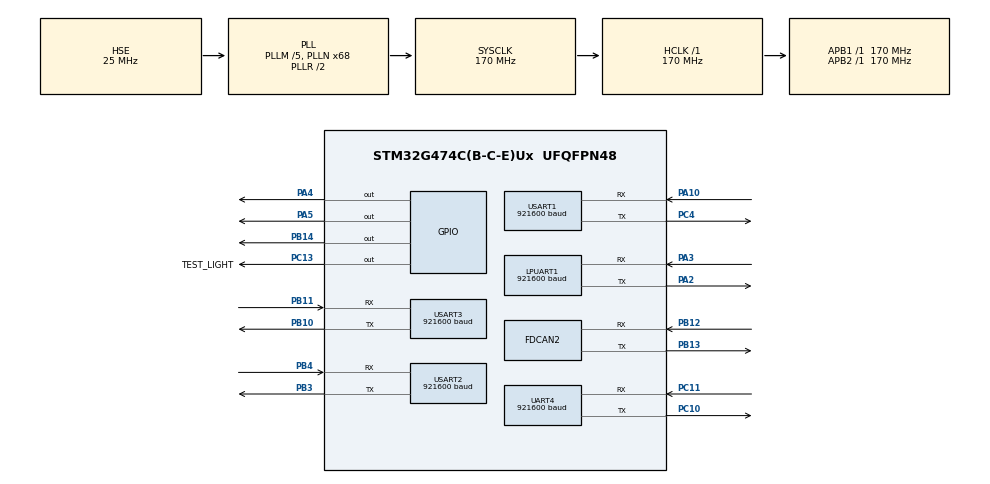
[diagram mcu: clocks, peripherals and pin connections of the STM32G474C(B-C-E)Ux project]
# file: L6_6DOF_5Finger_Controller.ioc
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Dma.LPUART1_RX.6.Direction=DMA_PERIPH_TO_MEMORY
Dma.LPUART1_RX.6.EventEnable=DISABLE
Dma.LPUART1_RX.6.Instance=DMA1_Channel3
Dma.LPUART1_RX.6.MemDataAlignment=DMA_MDATAALIGN_BYTE
Dma.LPUART1_RX.6.MemInc=DMA_MINC_ENABLE
Dma.LPUART1_RX.6.Mode=DMA_NORMAL
Dma.LPUART1_RX.6.PeriphDataAlignment=DMA_PDATAALIGN_BYTE
Dma.LPUART1_RX.6.PeriphInc=DMA_PINC_DISABLE
Dma.LPUART1_RX.6.Polarity=HAL_DMAMUX_REQ_GEN_RISING
Dma.LPUART1_RX.6.Priority=DMA_PRIORITY_MEDIUM
Dma.LPUART1_RX.6.RequestNumber=1
Dma.LPUART1_RX.6.SignalID=NONE
Dma.LPUART1_RX.6.SyncEnable=DISABLE
Dma.LPUART1_RX.6.SyncPolarity=HAL_DMAMUX_SYNC_NO_EVENT
Dma.LPUART1_RX.6.SyncRequestNumber=1
Dma.LPUART1_RX.6.SyncSignalID=NONE
Dma.LPUART1_TX.7.Direction=DMA_MEMORY_TO_PERIPH
Dma.LPUART1_TX.7.EventEnable=DISABLE
Dma.LPUART1_TX.7.Instance=DMA1_Channel4
Dma.LPUART1_TX.7.MemDataAlignment=DMA_MDATAALIGN_BYTE
Dma.LPUART1_TX.7.MemInc=DMA_MINC_ENABLE
Dma.LPUART1_TX.7.Mode=DMA_NORMAL
Dma.LPUART1_TX.7.PeriphDataAlignment=DMA_PDATAALIGN_BYTE
Dma.LPUART1_TX.7.PeriphInc=DMA_PINC_DISABLE
Dma.LPUART1_TX.7.Polarity=HAL_DMAMUX_REQ_GEN_RISING
Dma.LPUART1_TX.7.Priority=DMA_PRIORITY_MEDIUM
Dma.LPUART1_TX.7.RequestNumber=1
Dma.LPUART1_TX.7.SignalID=NONE
Dma.LPUART1_TX.7.SyncEnable=DISABLE
Dma.LPUART1_TX.7.SyncPolarity=HAL_DMAMUX_SYNC_NO_EVENT
Dma.LPUART1_TX.7.SyncRequestNumber=1
Dma.LPUART1_TX.7.SyncSignalID=NONE
Dma.Request0=USART2_RX
Dma.Request1=USART2_TX
Dma.Request2=USART3_RX
Dma.Request3=USART3_TX
Dma.Request4=UART4_RX
Dma.Request5=UART4_TX
Dma.Request6=LPUART1_RX
Dma.Request7=LPUART1_TX
Dma.UART4_RX.4.Direction=DMA_PERIPH_TO_MEMORY
Dma.UART4_RX.4.EventEnable=DISABLE
Dma.UART4_RX.4.Instance=DMA1_Channel7
Dma.UART4_RX.4.MemDataAlignment=DMA_MDATAALIGN_BYTE
Dma.UART4_RX.4.MemInc=DMA_MINC_ENABLE
Dma.UART4_RX.4.Mode=DMA_NORMAL
Dma.UART4_RX.4.PeriphDataAlignment=DMA_PDATAALIGN_BYTE
Dma.UART4_RX.4.PeriphInc=DMA_PINC_DISABLE
Dma.UART4_RX.4.Polarity=HAL_DMAMUX_REQ_GEN_RISING
Dma.UART4_RX.4.Priority=DMA_PRIORITY_MEDIUM
Dma.UART4_RX.4.RequestNumber=1
Dma.UART4_RX.4.SignalID=NONE
Dma.UART4_RX.4.SyncEnable=DISABLE
Dma.UART4_RX.4.SyncPolarity=HAL_DMAMUX_SYNC_NO_EVENT
Dma.UART4_RX.4.SyncRequestNumber=1
Dma.UART4_RX.4.SyncSignalID=NONE
Dma.UART4_TX.5.Direction=DMA_MEMORY_TO_PERIPH
Dma.UART4_TX.5.EventEnable=DISABLE
Dma.UART4_TX.5.Instance=DMA1_Channel8
Dma.UART4_TX.5.MemDataAlignment=DMA_MDATAALIGN_BYTE
Dma.UART4_TX.5.MemInc=DMA_MINC_ENABLE
Dma.UART4_TX.5.Mode=DMA_NORMAL
Dma.UART4_TX.5.PeriphDataAlignment=DMA_PDATAALIGN_BYTE
Dma.UART4_TX.5.PeriphInc=DMA_PINC_DISABLE
Dma.UART4_TX.5.Polarity=HAL_DMAMUX_REQ_GEN_RISING
Dma.UART4_TX.5.Priority=DMA_PRIORITY_MEDIUM
Dma.UART4_TX.5.RequestNumber=1
Dma.UART4_TX.5.SignalID=NONE
Dma.UART4_TX.5.SyncEnable=DISABLE
Dma.UART4_TX.5.SyncPolarity=HAL_DMAMUX_SYNC_NO_EVENT
Dma.UART4_TX.5.SyncRequestNumber=1
Dma.UART4_TX.5.SyncSignalID=NONE
Dma.USART2_RX.0.Direction=DMA_PERIPH_TO_MEMORY
Dma.USART2_RX.0.EventEnable=DISABLE
Dma.USART2_RX.0.Instance=DMA1_Channel1
Dma.USART2_RX.0.MemDataAlignment=DMA_MDATAALIGN_BYTE
Dma.USART2_RX.0.MemInc=DMA_MINC_ENABLE
Dma.USART2_RX.0.Mode=DMA_NORMAL
Dma.USART2_RX.0.PeriphDataAlignment=DMA_PDATAALIGN_BYTE
Dma.USART2_RX.0.PeriphInc=DMA_PINC_DISABLE
Dma.USART2_RX.0.Polarity=HAL_DMAMUX_REQ_GEN_RISING
Dma.USART2_RX.0.Priority=DMA_PRIORITY_MEDIUM
Dma.USART2_RX.0.RequestNumber=1
Dma.USART2_RX.0.SignalID=NONE
Dma.USART2_RX.0.SyncEnable=DISABLE
Dma.USART2_RX.0.SyncPolarity=HAL_DMAMUX_SYNC_NO_EVENT
Dma.USART2_RX.0.SyncRequestNumber=1
Dma.USART2_RX.0.SyncSignalID=NONE
Dma.USART2_TX.1.Direction=DMA_MEMORY_TO_PERIPH
Dma.USART2_TX.1.EventEnable=DISABLE
Dma.USART2_TX.1.Instance=DMA1_Channel2
Dma.USART2_TX.1.MemDataAlignment=DMA_MDATAALIGN_BYTE
Dma.USART2_TX.1.MemInc=DMA_MINC_ENABLE
Dma.USART2_TX.1.Mode=DMA_NORMAL
Dma.USART2_TX.1.PeriphDataAlignment=DMA_PDATAALIGN_BYTE
Dma.USART2_TX.1.PeriphInc=DMA_PINC_DISABLE
Dma.USART2_TX.1.Polarity=HAL_DMAMUX_REQ_GEN_RISING
Dma.USART2_TX.1.Priority=DMA_PRIORITY_MEDIUM
Dma.USART2_TX.1.RequestNumber=1
Dma.USART2_TX.1.SignalID=NONE
Dma.USART2_TX.1.SyncEnable=DISABLE
Dma.USART2_TX.1.SyncPolarity=HAL_DMAMUX_SYNC_NO_EVENT
Dma.USART2_TX.1.SyncRequestNumber=1
Dma.USART2_TX.1.SyncSignalID=NONE
Dma.USART3_RX.2.Direction=DMA_PERIPH_TO_MEMORY
Dma.USART3_RX.2.EventEnable=DISABLE
Dma.USART3_RX.2.Instance=DMA1_Channel5
Dma.USART3_RX.2.MemDataAlignment=DMA_MDATAALIGN_BYTE
Dma.USART3_RX.2.MemInc=DMA_MINC_ENABLE
Dma.USART3_RX.2.Mode=DMA_NORMAL
Dma.USART3_RX.2.PeriphDataAlignment=DMA_PDATAALIGN_BYTE
Dma.USART3_RX.2.PeriphInc=DMA_PINC_DISABLE
Dma.USART3_RX.2.Polarity=HAL_DMAMUX_REQ_GEN_RISING
Dma.USART3_RX.2.Priority=DMA_PRIORITY_MEDIUM
Dma.USART3_RX.2.RequestNumber=1
Dma.USART3_RX.2.SignalID=NONE
Dma.USART3_RX.2.SyncEnable=DISABLE
Dma.USART3_RX.2.SyncPolarity=HAL_DMAMUX_SYNC_NO_EVENT
Dma.USART3_RX.2.SyncRequestNumber=1
Dma.USART3_RX.2.SyncSignalID=NONE
Dma.USART3_TX.3.Direction=DMA_MEMORY_TO_PERIPH
Dma.USART3_TX.3.EventEnable=DISABLE
Dma.USART3_TX.3.Instance=DMA1_Channel6
Dma.USART3_TX.3.MemDataAlignment=DMA_MDATAALIGN_BYTE
Dma.USART3_TX.3.MemInc=DMA_MINC_ENABLE
Dma.USART3_TX.3.Mode=DMA_NORMAL
Dma.USART3_TX.3.PeriphDataAlignment=DMA_PDATAALIGN_BYTE
Dma.USART3_TX.3.PeriphInc=DMA_PINC_DISABLE
Dma.USART3_TX.3.Polarity=HAL_DMAMUX_REQ_GEN_RISING
Dma.USART3_TX.3.Priority=DMA_PRIORITY_MEDIUM
Dma.USART3_TX.3.RequestNumber=1
Dma.USART3_TX.3.SignalID=NONE
Dma.USART3_TX.3.SyncEnable=DISABLE
Dma.USART3_TX.3.SyncPolarity=HAL_DMAMUX_SYNC_NO_EVENT
Dma.USART3_TX.3.SyncRequestNumber=1
Dma.USART3_TX.3.SyncSignalID=NONE
FDCAN2.CalculateBaudRateNominal=999999
FDCAN2.CalculateTimeBitNominal=1000
FDCAN2.CalculateTimeQuantumNominal=58.82352941176471
FDCAN2.DataPrescaler=1
FDCAN2.DataTimeSeg1=1
FDCAN2.DataTimeSeg2=1
FDCAN2.ExtFiltersNbr=8
FDCAN2.FrameFormat=FDCAN_FRAME_CLASSIC
FDCAN2.NominalPrescaler=10
FDCAN2.NominalSyncJumpWidth=1
FDCAN2.NominalTimeSeg1=8
FDCAN2.NominalTimeSeg2=8
FDCAN2.StdFiltersNbr=28
FREERTOS.BinarySemaphores01=TipSensorTxSem,Dynamic,NULL,Available;TipSensorRxBlockSem,Dynamic,NULL,Available;UpperControlSem,Dynamic,NULL,Available;TJ_UART_RX_Sem,Dynamic,NULL,Available;TJ_Trans_Sem,Dynamic,NULL,Available
FREERTOS.Events01=DecodeEvent,Dynamic,NULL;UART_ReceivedEvent,Dynamic,NULL
FREERTOS.Queues01=Tip_Usart_Queue,5,153,1,Dynamic,NULL,NULL;Can_RX_Queue,16,10,1,Dynamic,NULL,NULL
FREERTOS.Tasks01=defaultTask,24,128,StartDefaultTask,As weak,NULL,Dynamic,NULL,NULL;MtParserTask,40,128,MotorDataParserTaskFun,As weak,NULL,Dynamic,NULL,NULL;MtControlTask,40,128,MotorControlTaskFun,As weak,NULL,Dynamic,NULL,NULL;TipSensorTask,24,128,StartTipSensorTask,As weak,NULL,Dynamic,NULL,NULL;TipRxDecodeTask,24,128,StartTipRxDecodeTask,As weak,NULL,Dynamic,NULL,NULL;TipSensorRespon,24,128,StartTipSensorRespon,As weak,NULL,Dynamic,NULL,NULL;CanAnalysisTask,24,128,StartCanAnalysisTask,As weak,NULL,Dynamic,NULL,NULL;UpperControlTas,24,128,StartUpperControlTask,As weak,NULL,Dynamic,NULL,NULL
FREERTOS.configTOTAL_HEAP_SIZE=10000
LPUART1.BaudRate=921600
Mcu.Family=STM32G4
Mcu.Name=STM32G474C(B-C-E)Ux
Mcu.Package=UFQFPN48
Mcu.UserConstants=TIP_USART,hlpuart1
NVIC.DMA1_Channel1_IRQn=true\:5\:0\:false\:false\:true\:true\:false\:true\:true
NVIC.DMA1_Channel2_IRQn=true\:5\:0\:false\:false\:true\:true\:false\:true\:true
NVIC.DMA1_Channel3_IRQn=true\:5\:0\:false\:false\:true\:true\:false\:true\:true
NVIC.DMA1_Channel4_IRQn=true\:5\:0\:false\:false\:true\:true\:false\:true\:true
NVIC.DMA1_Channel5_IRQn=true\:5\:0\:false\:false\:true\:true\:false\:true\:true
NVIC.DMA1_Channel6_IRQn=true\:5\:0\:false\:false\:true\:true\:false\:true\:true
NVIC.DMA1_Channel7_IRQn=true\:5\:0\:false\:false\:true\:true\:false\:true\:true
NVIC.DMA1_Channel8_IRQn=true\:5\:0\:false\:false\:true\:true\:false\:true\:true
NVIC.FDCAN2_IT0_IRQn=true\:5\:0\:false\:false\:true\:true\:true\:true\:true
NVIC.LPUART1_IRQn=true\:5\:0\:false\:false\:true\:true\:true\:true\:true
NVIC.PriorityGroup=NVIC_PRIORITYGROUP_4
NVIC.TIM1_UP_TIM16_IRQn=true\:15\:0\:false\:false\:true\:false\:false\:true\:true
NVIC.TimeBase=TIM1_UP_TIM16_IRQn
NVIC.TimeBaseIP=TIM1
NVIC.UART4_IRQn=true\:5\:0\:false\:false\:true\:true\:true\:true\:true
NVIC.USART1_IRQn=true\:5\:0\:false\:false\:true\:true\:false\:true\:true
NVIC.USART2_IRQn=true\:5\:0\:false\:false\:true\:true\:false\:true\:true
NVIC.USART3_IRQn=true\:5\:0\:false\:false\:true\:true\:true\:true\:true
PA10.GPIO_PuPd=GPIO_PULLUP
PA10.GPIO_Speed=GPIO_SPEED_FREQ_HIGH
PA10.Mode=Asynchronous
PA10.Signal=USART1_RX
PA13.Mode=Serial_Wire
PA13.Signal=SYS_JTMS-SWDIO
PA14.Mode=Serial_Wire
PA14.Signal=SYS_JTCK-SWCLK
PA2.Mode=Asynchronous
PA2.Signal=LPUART1_TX
PA3.GPIO_PuPd=GPIO_NOPULL
PA3.Mode=Asynchronous
PA3.Signal=LPUART1_RX
PA4.PinState=GPIO_PIN_SET
PA4.Signal=GPIO_Output
PA5.PinState=GPIO_PIN_SET
PA5.Signal=GPIO_Output
PB10.GPIO_PuPd=GPIO_NOPULL
PB10.GPIO_Speed=GPIO_SPEED_FREQ_HIGH
PB10.Mode=Asynchronous
PB10.Signal=USART3_TX
PB11.GPIO_PuPd=GPIO_PULLUP
PB11.GPIO_Speed=GPIO_SPEED_FREQ_HIGH
PB11.Mode=Asynchronous
PB11.Signal=USART3_RX
PB12.Mode=FDCAN_Activate
PB12.Signal=FDCAN2_RX
PB13.Mode=FDCAN_Activate
PB13.Signal=FDCAN2_TX
PB14.GPIO_PuPd=GPIO_PULLDOWN
PB14.GPIO_Speed=GPIO_SPEED_FREQ_HIGH
PB14.Signal=GPIO_Output
PB3.GPIO_ModeDefaultPP=GPIO_MODE_AF_PP
PB3.GPIO_PuPd=GPIO_NOPULL
PB3.GPIO_Speed=GPIO_SPEED_FREQ_HIGH
PB3.Mode=Asynchronous
PB3.Signal=USART2_TX
PB4.GPIO_PuPd=GPIO_PULLUP
PB4.GPIO_Speed=GPIO_SPEED_FREQ_HIGH
PB4.Mode=Asynchronous
PB4.Signal=USART2_RX
PC10.GPIO_PuPd=GPIO_NOPULL
PC10.GPIO_Speed=GPIO_SPEED_FREQ_HIGH
PC10.Mode=Asynchronous
PC10.Signal=UART4_TX
PC11.GPIO_PuPd=GPIO_PULLUP
PC11.GPIO_Speed=GPIO_SPEED_FREQ_HIGH
PC11.Mode=Asynchronous
PC11.Signal=UART4_RX
PC13.GPIO_Label=TEST_LIGHT
PC13.GPIO_ModeDefaultOutputPP=GPIO_MODE_OUTPUT_PP
PC13.GPIO_PuPd=GPIO_NOPULL
PC13.GPIO_Speed=GPIO_SPEED_FREQ_LOW
PC13.PinState=GPIO_PIN_SET
PC13.Signal=GPIO_Output
PC4.GPIO_Speed=GPIO_SPEED_FREQ_HIGH
PC4.Mode=Asynchronous
PC4.Signal=USART1_TX
PF0-OSC_IN.Mode=HSE-External-Oscillator
PF0-OSC_IN.Signal=RCC_OSC_IN
PF1-OSC_OUT.Mode=HSE-External-Oscillator
PF1-OSC_OUT.Signal=RCC_OSC_OUT
ProjectManager.HeapSize=0x600
ProjectManager.StackSize=0x400
ProjectManager.TargetToolchain=MDK-ARM V5.32
RCC.ADC12Freq_Value=170000000
RCC.ADC345Freq_Value=170000000
RCC.AHBFreq_Value=170000000
RCC.APB1Freq_Value=170000000
RCC.APB1TimFreq_Value=170000000
RCC.APB2Freq_Value=170000000
RCC.APB2TimFreq_Value=170000000
RCC.CortexFreq_Value=170000000
RCC.EXTERNAL_CLOCK_VALUE=12288000
RCC.HCLKFreq_Value=170000000
RCC.HSE_VALUE=25000000
RCC.HSI48_VALUE=48000000
RCC.HSI_VALUE=16000000
RCC.LSE_VALUE=32768
RCC.PLLM=RCC_PLLM_DIV5
RCC.PLLN=68
RCC.PLLQ=RCC_PLLQ_DIV4
RCC.PLLSourceVirtual=RCC_PLLSOURCE_HSE
RCC.SYSCLKFreq_VALUE=170000000
RCC.SYSCLKSource=RCC_SYSCLKSOURCE_PLLCLK
RCC.USBFreq_Value=85000000
RCC.VCOOutputFreq_Value=340000000
UART4.BaudRate=921600
USART1.BaudRate=921600
USART1.VirtualMode-Asynchronous=VM_ASYNC
USART2.BaudRate=921600
USART2.VirtualMode-Asynchronous=VM_ASYNC
USART3.BaudRate=921600
USART3.VirtualMode-Asynchronous=VM_ASYNC
VP_FREERTOS_VS_CMSIS_V2.Mode=CMSIS_V2
VP_SYS_VS_DBSignals.Mode=DisableDeadBatterySignals
VP_SYS_VS_tim1.Mode=TIM1
board=custom

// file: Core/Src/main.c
/* USER CODE BEGIN Header */
/**
 ******************************************************************************
 * @file           : main.c
 * @brief          : Main program body
 ******************************************************************************
 * @attention
 *
 * Copyright (c) 2025 STMicroelectronics.
 * All rights reserved.
 *
 * This software is licensed under terms that can be found in the LICENSE file
 * in the root directory of this software component.
 * If no LICENSE file comes with this software, it is provided AS-IS.
 *
 ******************************************************************************
 */
/* USER CODE END Header */
#include "main.h"
#include "cmsis_os.h"
#include "dma.h"
#include "fdcan.h"
#include "usart.h"
#include "gpio.h"

void SystemClock_Config(void);
void MX_FREERTOS_Init(void);

int main(void)
{

  /* MCU Configuration--------------------------------------------------------*/

  /* Reset of all peripherals, Initializes the Flash interface and the Systick. */
  HAL_Init();

  /* USER CODE BEGIN Init */
	//HAL_Delay(1000);
  /* USER CODE END Init */

  /* Configure the system clock */
  SystemClock_Config();

  /* Initialize all configured peripherals */
  MX_GPIO_Init();
  MX_DMA_Init();
  MX_FDCAN2_Init();
  MX_LPUART1_UART_Init();
  MX_USART1_UART_Init();
  MX_UART4_Init();
  MX_USART2_UART_Init();
  MX_USART3_UART_Init();

  /* Init scheduler */
  osKernelInitialize();

  /* Call init function for freertos objects (in cmsis_os2.c) */
  MX_FREERTOS_Init();

  /* Start scheduler */
  osKernelStart();

  /* We should never get here as control is now taken by the scheduler */

  /* Infinite loop */
  while (1)
  {

  }
}

void SystemClock_Config(void)
{
  RCC_OscInitTypeDef RCC_OscInitStruct = {0};
  RCC_ClkInitTypeDef RCC_ClkInitStruct = {0};

  /** Configure the main internal regulator output voltage
  */
  HAL_PWREx_ControlVoltageScaling(PWR_REGULATOR_VOLTAGE_SCALE1_BOOST);

  /** Initializes the RCC Oscillators according to the specified parameters
  * in the RCC_OscInitTypeDef structure.
  */
  RCC_OscInitStruct.OscillatorType = RCC_OSCILLATORTYPE_HSE;
  RCC_OscInitStruct.HSEState = RCC_HSE_ON;
  RCC_OscInitStruct.PLL.PLLState = RCC_PLL_ON;
  RCC_OscInitStruct.PLL.PLLSource = RCC_PLLSOURCE_HSE;
  RCC_OscInitStruct.PLL.PLLM = RCC_PLLM_DIV5;
  RCC_OscInitStruct.PLL.PLLN = 68;
  RCC_OscInitStruct.PLL.PLLP = RCC_PLLP_DIV2;
  RCC_OscInitStruct.PLL.PLLQ = RCC_PLLQ_DIV4;
  RCC_OscInitStruct.PLL.PLLR = RCC_PLLR_DIV2;
  if (HAL_RCC_OscConfig(&RCC_OscInitStruct) != HAL_OK)
  {
    Error_Handler();
  }

  /** Initializes the CPU, AHB and APB buses clocks
  */
  RCC_ClkInitStruct.ClockType = RCC_CLOCKTYPE_HCLK|RCC_CLOCKTYPE_SYSCLK
                              |RCC_CLOCKTYPE_PCLK1|RCC_CLOCKTYPE_PCLK2;
  RCC_ClkInitStruct.SYSCLKSource = RCC_SYSCLKSOURCE_PLLCLK;
  RCC_ClkInitStruct.AHBCLKDivider = RCC_SYSCLK_DIV1;
  RCC_ClkInitStruct.APB1CLKDivider = RCC_HCLK_DIV1;
  RCC_ClkInitStruct.APB2CLKDivider = RCC_HCLK_DIV1;

  if (HAL_RCC_ClockConfig(&RCC_ClkInitStruct, FLASH_LATENCY_4) != HAL_OK)
  {
    Error_Handler();
  }
}

void HAL_TIM_PeriodElapsedCallback(TIM_HandleTypeDef *htim)
{
  if (htim->Instance == TIM1)
  {
    HAL_IncTick();
  }
}

void Error_Handler(void)
{
  __disable_irq();
  while (1)
  {
  }
}

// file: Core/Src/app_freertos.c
/* USER CODE BEGIN Header */
/**
  ******************************************************************************
  * File Name          : app_freertos.c
  * Description        : Code for freertos applications
  ******************************************************************************
  * @attention
  *
  * Copyright (c) 2025 STMicroelectronics.
  * All rights reserved.
  *
  * This software is licensed under terms that can be found in the LICENSE file
  * in the root directory of this software component.
  * If no LICENSE file comes with this software, it is provided AS-IS.
  *
  ******************************************************************************
  */
/* USER CODE END Header */

#include "FreeRTOS.h"
#include "task.h"
#include "main.h"
#include "cmsis_os.h"

/* Definitions for defaultTask */
osThreadId_t defaultTaskHandle;
const osThreadAttr_t defaultTask_attributes = {
  .name = "defaultTask",
  .priority = (osPriority_t) osPriorityNormal,
  .stack_size = 128 * 4
};
/* Definitions for MtParserTask */
osThreadId_t MtParserTaskHandle;
const osThreadAttr_t MtParserTask_attributes = {
  .name = "MtParserTask",
  .priority = (osPriority_t) osPriorityHigh,
  .stack_size = 128 * 4
};
/* Definitions for MtControlTask */
osThreadId_t MtControlTaskHandle;
const osThreadAttr_t MtControlTask_attributes = {
  .name = "MtControlTask",
  .priority = (osPriority_t) osPriorityHigh,
  .stack_size = 128 * 4
};
/* Definitions for TipSensorTask */
osThreadId_t TipSensorTaskHandle;
const osThreadAttr_t TipSensorTask_attributes = {
  .name = "TipSensorTask",
  .priority = (osPriority_t) osPriorityNormal,
  .stack_size = 128 * 4
};
/* Definitions for TipRxDecodeTask */
osThreadId_t TipRxDecodeTaskHandle;
const osThreadAttr_t TipRxDecodeTask_attributes = {
  .name = "TipRxDecodeTask",
  .priority = (osPriority_t) osPriorityNormal,
  .stack_size = 128 * 4
};
/* Definitions for TipSensorRespon */
osThreadId_t TipSensorResponHandle;
const osThreadAttr_t TipSensorRespon_attributes = {
  .name = "TipSensorRespon",
  .priority = (osPriority_t) osPriorityNormal,
  .stack_size = 128 * 4
};
/* Definitions for CanAnalysisTask */
osThreadId_t CanAnalysisTaskHandle;
const osThreadAttr_t CanAnalysisTask_attributes = {
  .name = "CanAnalysisTask",
  .priority = (osPriority_t) osPriorityNormal,
  .stack_size = 128 * 4
};
/* Definitions for UpperControlTas */
osThreadId_t UpperControlTasHandle;
const osThreadAttr_t UpperControlTas_attributes = {
  .name = "UpperControlTas",
  .priority = (osPriority_t) osPriorityNormal,
  .stack_size = 128 * 4
};
/* Definitions for Tip_Usart_Queue */
osMessageQueueId_t Tip_Usart_QueueHandle;
const osMessageQueueAttr_t Tip_Usart_Queue_attributes = {
  .name = "Tip_Usart_Queue"
};
/* Definitions for Can_RX_Queue */
osMessageQueueId_t Can_RX_QueueHandle;
const osMessageQueueAttr_t Can_RX_Queue_attributes = {
  .name = "Can_RX_Queue"
};
/* Definitions for TipSensorTxSem */
osSemaphoreId_t TipSensorTxSemHandle;
const osSemaphoreAttr_t TipSensorTxSem_attributes = {
  .name = "TipSensorTxSem"
};
/* Definitions for TipSensorRxBlockSem */
osSemaphoreId_t TipSensorRxBlockSemHandle;
const osSemaphoreAttr_t TipSensorRxBlockSem_attributes = {
  .name = "TipSensorRxBlockSem"
};
/* Definitions for UpperControlSem */
osSemaphoreId_t UpperControlSemHandle;
const osSemaphoreAttr_t UpperControlSem_attributes = {
  .name = "UpperControlSem"
};
/* Definitions for TJ_UART_RX_Sem */
osSemaphoreId_t TJ_UART_RX_SemHandle;
const osSemaphoreAttr_t TJ_UART_RX_Sem_attributes = {
  .name = "TJ_UART_RX_Sem"
};
/* Definitions for TJ_Trans_Sem */
osSemaphoreId_t TJ_Trans_SemHandle;
const osSemaphoreAttr_t TJ_Trans_Sem_attributes = {
  .name = "TJ_Trans_Sem"
};
/* Definitions for DecodeEvent */
osEventFlagsId_t DecodeEventHandle;
const osEventFlagsAttr_t DecodeEvent_attributes = {
  .name = "DecodeEvent"
};
/* Definitions for UART_ReceivedEvent */
osEventFlagsId_t UART_ReceivedEventHandle;
const osEventFlagsAttr_t UART_ReceivedEvent_attributes = {
  .name = "UART_ReceivedEvent"
};

void StartDefaultTask(void *argument);
void MotorDataParserTaskFun(void *argument);
void MotorControlTaskFun(void *argument);
void StartTipSensorTask(void *argument);
void StartTipRxDecodeTask(void *argument);
void StartTipSensorRespon(void *argument);
void StartCanAnalysisTask(void *argument);
void StartUpperControlTask(void *argument);

void MX_FREERTOS_Init(void); /* (MISRA C 2004 rule 8.1) */

void MX_FREERTOS_Init(void) {

  /* Create the semaphores(s) */
  /* creation of TipSensorTxSem */
  TipSensorTxSemHandle = osSemaphoreNew(1, 1, &TipSensorTxSem_attributes);

  /* creation of TipSensorRxBlockSem */
  TipSensorRxBlockSemHandle = osSemaphoreNew(1, 1, &TipSensorRxBlockSem_attributes);

  /* creation of UpperControlSem */
  UpperControlSemHandle = osSemaphoreNew(1, 1, &UpperControlSem_attributes);

  /* creation of TJ_UART_RX_Sem */
  TJ_UART_RX_SemHandle = osSemaphoreNew(1, 1, &TJ_UART_RX_Sem_attributes);

  /* creation of TJ_Trans_Sem */
  TJ_Trans_SemHandle = osSemaphoreNew(1, 1, &TJ_Trans_Sem_attributes);

  /* Create the queue(s) */
  /* creation of Tip_Usart_Queue */
  Tip_Usart_QueueHandle = osMessageQueueNew (5, 153, &Tip_Usart_Queue_attributes);

  /* creation of Can_RX_Queue */
  Can_RX_QueueHandle = osMessageQueueNew (16, 10, &Can_RX_Queue_attributes);

  /* Create the thread(s) */
  /* creation of defaultTask */
  defaultTaskHandle = osThreadNew(StartDefaultTask, NULL, &defaultTask_attributes);

  /* creation of MtParserTask */
  MtParserTaskHandle = osThreadNew(MotorDataParserTaskFun, NULL, &MtParserTask_attributes);

  /* creation of MtControlTask */
  MtControlTaskHandle = osThreadNew(MotorControlTaskFun, NULL, &MtControlTask_attributes);

  /* creation of TipSensorTask */
  TipSensorTaskHandle = osThreadNew(StartTipSensorTask, NULL, &TipSensorTask_attributes);

  /* creation of TipRxDecodeTask */
  TipRxDecodeTaskHandle = osThreadNew(StartTipRxDecodeTask, NULL, &TipRxDecodeTask_attributes);

  /* creation of TipSensorRespon */
  TipSensorResponHandle = osThreadNew(StartTipSensorRespon, NULL, &TipSensorRespon_attributes);

  /* creation of CanAnalysisTask */
  CanAnalysisTaskHandle = osThreadNew(StartCanAnalysisTask, NULL, &CanAnalysisTask_attributes);

  /* creation of UpperControlTas */
  UpperControlTasHandle = osThreadNew(StartUpperControlTask, NULL, &UpperControlTas_attributes);

  /* Create the event(s) */
  /* creation of DecodeEvent */
  DecodeEventHandle = osEventFlagsNew(&DecodeEvent_attributes);

  /* creation of UART_ReceivedEvent */
  UART_ReceivedEventHandle = osEventFlagsNew(&UART_ReceivedEvent_attributes);

}

__weak void StartDefaultTask(void *argument)
{
  for(;;)
  {
    osDelay(1);
  }
}

__weak void MotorDataParserTaskFun(void *argument)
{
  for(;;)
  {
    osDelay(1);
  }
}

__weak void MotorControlTaskFun(void *argument)
{
  for(;;)
  {
    osDelay(1);
  }
}

__weak void StartTipSensorTask(void *argument)
{
  for(;;)
  {
    osDelay(1);
  }
}

__weak void StartTipRxDecodeTask(void *argument)
{
  for(;;)
  {
    osDelay(1);
  }
}

__weak void StartTipSensorRespon(void *argument)
{
  for(;;)
  {
    osDelay(1);
  }
}

__weak void StartCanAnalysisTask(void *argument)
{
  for(;;)
  {
    osDelay(1);
  }
}

__weak void StartUpperControlTask(void *argument)
{
  for(;;)
  {
    osDelay(1);
  }
}
